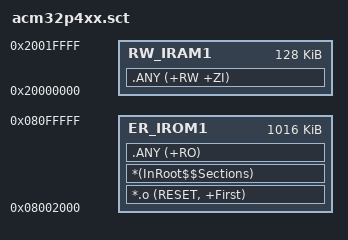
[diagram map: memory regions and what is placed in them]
;************************************************************
; *** Scatter-Loading Description File for ACM32P4XX
; *** Flash: 0x08002000, Size: 0xFE000 (~1016KB)
; *** SRAM:  0x20000000, Size: 0x20000 (128KB)
;************************************************************

LR_IROM1 0x08002000 0x000FE000  {    ; load region size_region
  ER_IROM1 0x08002000 0x000FE000  {  ; load address = execution address
   *.o (RESET, +First)
   *(InRoot$$Sections)
   .ANY (+RO)
  }
  RW_IRAM1 0x20000000 0x00020000  {  ; RW data
   .ANY (+RW +ZI)
  }
}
